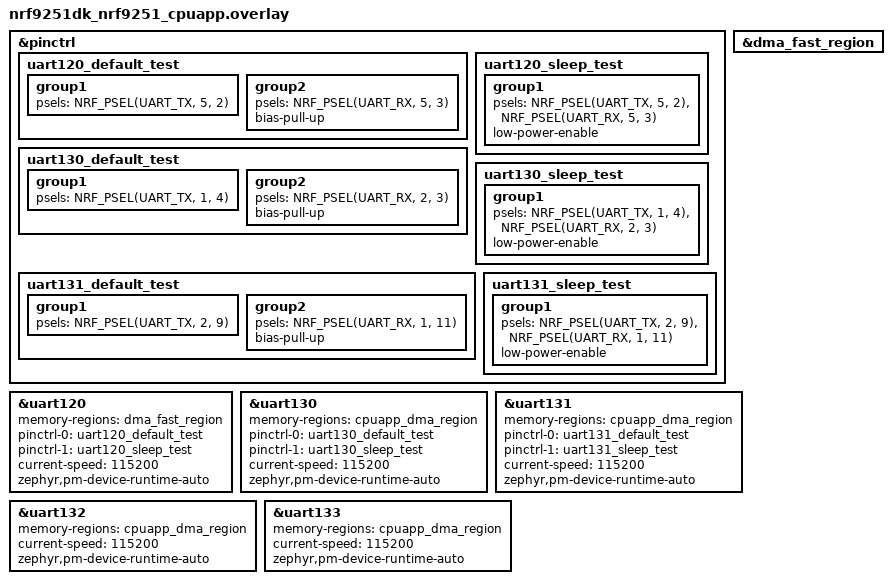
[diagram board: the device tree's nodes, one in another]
/*
 * Copyright (c) 2026 Nordic Semiconductor ASA
 *
 * SPDX-License-Identifier: LicenseRef-Nordic-5-Clause
 */

&pinctrl {
	uart120_default_test: uart120_default_test {
		group1 {
			psels = <NRF_PSEL(UART_TX, 5, 2)>;
		};

		group2 {
			psels = <NRF_PSEL(UART_RX, 5, 3)>;
			bias-pull-up;
		};
	};

	uart120_sleep_test: uart120_sleep_test {
		group1 {
			psels = <NRF_PSEL(UART_TX, 5, 2)>,
				<NRF_PSEL(UART_RX, 5, 3)>;
			low-power-enable;
		};
	};

	uart130_default_test: uart130_default_test {
		group1 {
			psels = <NRF_PSEL(UART_TX, 1, 4)>;
		};

		group2 {
			psels = <NRF_PSEL(UART_RX, 2, 3)>;
			bias-pull-up;
		};
	};

	uart130_sleep_test: uart130_sleep_test {
		group1 {
			psels = <NRF_PSEL(UART_TX, 1, 4)>,
				<NRF_PSEL(UART_RX, 2, 3)>;
			low-power-enable;
		};
	};

	uart131_default_test: uart131_default_test {
		group1 {
			psels = <NRF_PSEL(UART_TX, 2, 9)>;
		};

		group2 {
			psels = <NRF_PSEL(UART_RX, 1, 11)>;
			bias-pull-up;
		};
	};

	uart131_sleep_test: uart131_sleep_test {
		group1 {
			psels = <NRF_PSEL(UART_TX, 2, 9)>,
				<NRF_PSEL(UART_RX, 1, 11)>;
			low-power-enable;
		};
	};

	/* use default pinctrl for uart132 */

	/* use default pinctrl for uart133 */
};

&uart120 {
	status = "okay";
	memory-regions = <&dma_fast_region>;
	pinctrl-0 = <&uart120_default_test>;
	pinctrl-1 = <&uart120_sleep_test>;
	pinctrl-names = "default", "sleep";
	current-speed = <115200>;
	zephyr,pm-device-runtime-auto;
};

&dma_fast_region {
	status = "okay";
};

&uart130 {
	status = "okay";
	memory-regions = <&cpuapp_dma_region>;
	pinctrl-0 = <&uart130_default_test>;
	pinctrl-1 = <&uart130_sleep_test>;
	pinctrl-names = "default", "sleep";
	current-speed = <115200>;
	zephyr,pm-device-runtime-auto;
};

&uart131 {
	status = "okay";
	memory-regions = <&cpuapp_dma_region>;
	pinctrl-0 = <&uart131_default_test>;
	pinctrl-1 = <&uart131_sleep_test>;
	pinctrl-names = "default", "sleep";
	current-speed = <115200>;
	zephyr,pm-device-runtime-auto;
};

&uart132 {
	status = "okay";
	memory-regions = <&cpuapp_dma_region>;
	current-speed = <115200>;
	zephyr,pm-device-runtime-auto;
};

&uart133 {
	status = "okay";
	memory-regions = <&cpuapp_dma_region>;
	current-speed = <115200>;
	zephyr,pm-device-runtime-auto;
};
